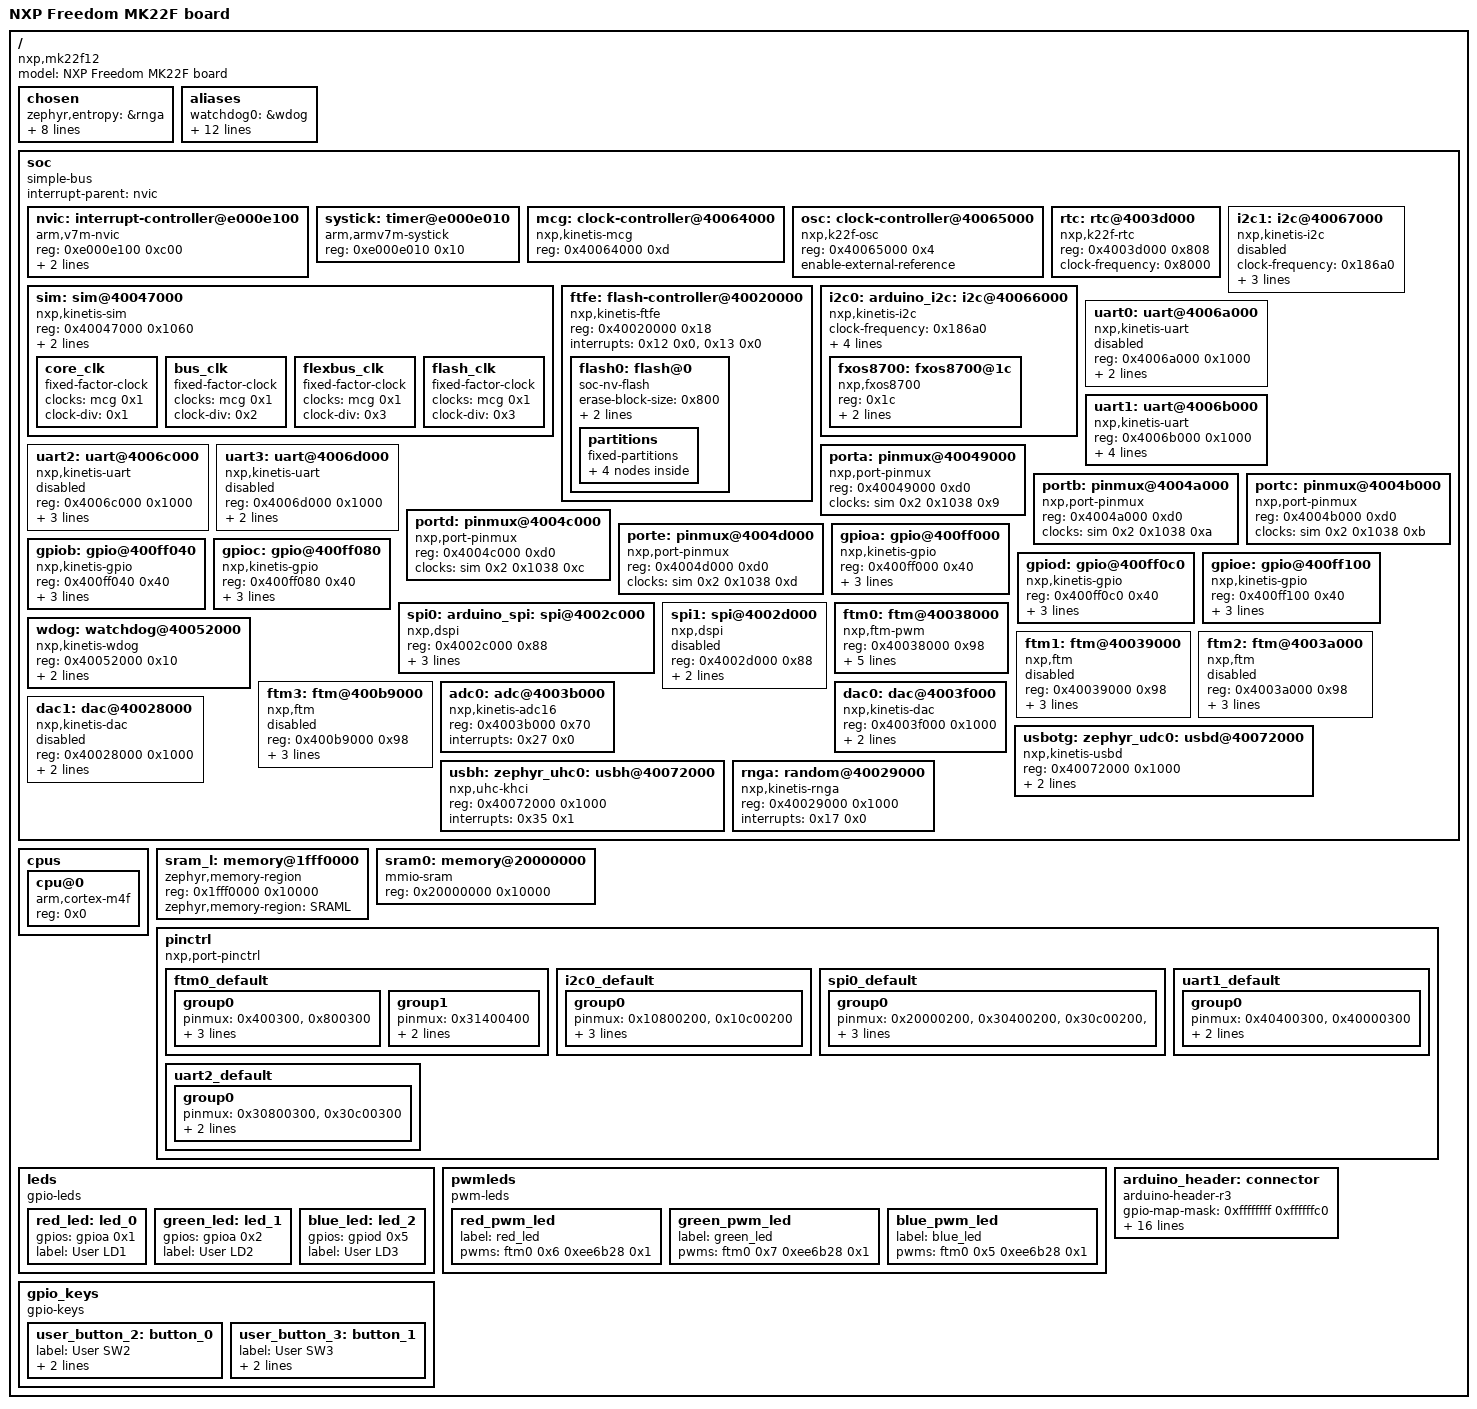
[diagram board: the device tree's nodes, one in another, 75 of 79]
/dts-v1/;

/* node '/' defined in zephyr/dts/common/skeleton.dtsi:9 */
/ {
	#address-cells = < 0x1 >;          /* in zephyr/dts/common/skeleton.dtsi:10 */
	#size-cells = < 0x1 >;             /* in zephyr/dts/common/skeleton.dtsi:11 */
	model = "NXP Freedom MK22F board"; /* in zephyr/boards/nxp/frdm_k22f/frdm_k22f.dts:17 */
	compatible = "nxp,mk22f12",
	             "nxp,k22f",
	             "nxp,k2x";            /* in zephyr/boards/nxp/frdm_k22f/frdm_k22f.dts:18 */

	/* node '/chosen' defined in zephyr/dts/common/skeleton.dtsi:13 */
	chosen {
		zephyr,entropy = &rnga;                   /* in zephyr/dts/arm/nxp/nxp_k2x.dtsi:19 */
		zephyr,flash-controller = &ftfe;          /* in zephyr/dts/arm/nxp/nxp_k2x.dtsi:20 */
		zephyr,sram = &sram0;                     /* in zephyr/boards/nxp/frdm_k22f/frdm_k22f.dts:36 */
		zephyr,flash = &flash0;                   /* in zephyr/boards/nxp/frdm_k22f/frdm_k22f.dts:37 */
		zephyr,code-partition = &slot0_partition; /* in zephyr/boards/nxp/frdm_k22f/frdm_k22f.dts:38 */
		zephyr,uart-mcumgr = &uart1;              /* in zephyr/boards/nxp/frdm_k22f/frdm_k22f.dts:39 */
		zephyr,console = &uart1;                  /* in zephyr/boards/nxp/frdm_k22f/frdm_k22f.dts:40 */
		zephyr,shell-uart = &uart1;               /* in zephyr/boards/nxp/frdm_k22f/frdm_k22f.dts:41 */
		zephyr,uart-pipe = &uart1;                /* in zephyr/boards/nxp/frdm_k22f/frdm_k22f.dts:42 */
	};

	/* node '/aliases' defined in zephyr/dts/common/skeleton.dtsi:15 */
	aliases {
		watchdog0 = &wdog;                /* in zephyr/dts/arm/nxp/nxp_k2x.dtsi:24 */
		led0 = &green_led;                /* in zephyr/boards/nxp/frdm_k22f/frdm_k22f.dts:21 */
		led1 = &blue_led;                 /* in zephyr/boards/nxp/frdm_k22f/frdm_k22f.dts:22 */
		led2 = &red_led;                  /* in zephyr/boards/nxp/frdm_k22f/frdm_k22f.dts:23 */
		sw0 = &user_button_3;             /* in zephyr/boards/nxp/frdm_k22f/frdm_k22f.dts:24 */
		sw1 = &user_button_2;             /* in zephyr/boards/nxp/frdm_k22f/frdm_k22f.dts:25 */
		pwm-led0 = &green_pwm_led;        /* in zephyr/boards/nxp/frdm_k22f/frdm_k22f.dts:26 */
		green-pwm-led = &green_pwm_led;   /* in zephyr/boards/nxp/frdm_k22f/frdm_k22f.dts:27 */
		blue-pwm-led = &blue_pwm_led;     /* in zephyr/boards/nxp/frdm_k22f/frdm_k22f.dts:28 */
		red-pwm-led = &red_pwm_led;       /* in zephyr/boards/nxp/frdm_k22f/frdm_k22f.dts:29 */
		magn0 = &fxos8700;                /* in zephyr/boards/nxp/frdm_k22f/frdm_k22f.dts:30 */
		accel0 = &fxos8700;               /* in zephyr/boards/nxp/frdm_k22f/frdm_k22f.dts:31 */
		mcuboot-button0 = &user_button_3; /* in zephyr/boards/nxp/frdm_k22f/frdm_k22f.dts:32 */
	};

	/* node '/soc' defined in zephyr/dts/arm/armv7-m.dtsi:6 */
	soc {
		#address-cells = < 0x1 >;     /* in zephyr/dts/arm/armv7-m.dtsi:7 */
		#size-cells = < 0x1 >;        /* in zephyr/dts/arm/armv7-m.dtsi:8 */
		compatible = "simple-bus";    /* in zephyr/dts/arm/armv7-m.dtsi:9 */
		interrupt-parent = < &nvic >; /* in zephyr/dts/arm/armv7-m.dtsi:10 */
		ranges;                       /* in zephyr/dts/arm/armv7-m.dtsi:11 */

		/* node '/soc/interrupt-controller@e000e100' defined in zephyr/dts/arm/armv7-m.dtsi:13 */
		nvic: interrupt-controller@e000e100 {
			#address-cells = < 0x1 >;            /* in zephyr/dts/arm/armv7-m.dtsi:14 */
			compatible = "arm,v7m-nvic";         /* in zephyr/dts/arm/armv7-m.dtsi:15 */
			reg = < 0xe000e100 0xc00 >;          /* in zephyr/dts/arm/armv7-m.dtsi:16 */
			interrupt-controller;                /* in zephyr/dts/arm/armv7-m.dtsi:17 */
			#interrupt-cells = < 0x2 >;          /* in zephyr/dts/arm/armv7-m.dtsi:18 */
			arm,num-irq-priority-bits = < 0x4 >; /* in zephyr/dts/arm/nxp/nxp_k2x.dtsi:398 */
			phandle = < 0x1 >;                   /* in zephyr/dts/arm/armv7-m.dtsi:10 */
		};

		/* node '/soc/timer@e000e010' defined in zephyr/dts/arm/armv7-m.dtsi:21 */
		systick: timer@e000e010 {
			compatible = "arm,armv7m-systick"; /* in zephyr/dts/arm/armv7-m.dtsi:22 */
			reg = < 0xe000e010 0x10 >;         /* in zephyr/dts/arm/armv7-m.dtsi:23 */
		};

		/* node '/soc/clock-controller@40064000' defined in zephyr/dts/arm/nxp/nxp_k2x.dtsi:65 */
		mcg: clock-controller@40064000 {
			compatible = "nxp,kinetis-mcg"; /* in zephyr/dts/arm/nxp/nxp_k2x.dtsi:66 */
			reg = < 0x40064000 0xd >;       /* in zephyr/dts/arm/nxp/nxp_k2x.dtsi:67 */
			#clock-cells = < 0x1 >;         /* in zephyr/dts/arm/nxp/nxp_k2x.dtsi:68 */
			phandle = < 0x2 >;              /* in zephyr/dts/arm/nxp/nxp_k2x.dtsi:91 */
		};

		/* node '/soc/clock-controller@40065000' defined in zephyr/dts/arm/nxp/nxp_k2x.dtsi:71 */
		osc: clock-controller@40065000 {
			compatible = "nxp,k22f-osc"; /* in zephyr/dts/arm/nxp/nxp_k2x.dtsi:72 */
			reg = < 0x40065000 0x4 >;    /* in zephyr/dts/arm/nxp/nxp_k2x.dtsi:73 */
			enable-external-reference;   /* in zephyr/dts/arm/nxp/nxp_k2x.dtsi:75 */
		};

		/* node '/soc/rtc@4003d000' defined in zephyr/dts/arm/nxp/nxp_k2x.dtsi:78 */
		rtc: rtc@4003d000 {
			compatible = "nxp,k22f-rtc";  /* in zephyr/dts/arm/nxp/nxp_k2x.dtsi:79 */
			reg = < 0x4003d000 0x808 >;   /* in zephyr/dts/arm/nxp/nxp_k2x.dtsi:80 */
			clock-frequency = < 0x8000 >; /* in zephyr/dts/arm/nxp/nxp_k2x.dtsi:81 */
		};

		/* node '/soc/sim@40047000' defined in zephyr/dts/arm/nxp/nxp_k2x.dtsi:84 */
		sim: sim@40047000 {
			compatible = "nxp,kinetis-sim"; /* in zephyr/dts/arm/nxp/nxp_k2x.dtsi:85 */
			reg = < 0x40047000 0x1060 >;    /* in zephyr/dts/arm/nxp/nxp_k2x.dtsi:86 */
			#clock-cells = < 0x3 >;         /* in zephyr/dts/arm/nxp/nxp_k2x.dtsi:87 */
			pllfll-select = < 0x1 >;        /* in zephyr/boards/nxp/frdm_k22f/frdm_k22f.dts:130 */
			er32k-select = < 0x2 >;         /* in zephyr/boards/nxp/frdm_k22f/frdm_k22f.dts:131 */
			phandle = < 0x3 >;              /* in zephyr/dts/arm/nxp/nxp_k2x.dtsi:143 */

			/* node '/soc/sim@40047000/core_clk' defined in zephyr/dts/arm/nxp/nxp_k2x.dtsi:89 */
			core_clk {
				compatible = "fixed-factor-clock"; /* in zephyr/dts/arm/nxp/nxp_k2x.dtsi:90 */
				clocks = < &mcg 0x1 >;             /* in zephyr/dts/arm/nxp/nxp_k2x.dtsi:91 */
				clock-div = < 0x1 >;               /* in zephyr/dts/arm/nxp/nxp_k2x.dtsi:92 */
				#clock-cells = < 0x0 >;            /* in zephyr/dts/arm/nxp/nxp_k2x.dtsi:93 */
			};

			/* node '/soc/sim@40047000/bus_clk' defined in zephyr/dts/arm/nxp/nxp_k2x.dtsi:96 */
			bus_clk {
				compatible = "fixed-factor-clock"; /* in zephyr/dts/arm/nxp/nxp_k2x.dtsi:97 */
				clocks = < &mcg 0x1 >;             /* in zephyr/dts/arm/nxp/nxp_k2x.dtsi:98 */
				clock-div = < 0x2 >;               /* in zephyr/dts/arm/nxp/nxp_k2x.dtsi:99 */
				#clock-cells = < 0x0 >;            /* in zephyr/dts/arm/nxp/nxp_k2x.dtsi:100 */
			};

			/* node '/soc/sim@40047000/flexbus_clk' defined in zephyr/dts/arm/nxp/nxp_k2x.dtsi:103 */
			flexbus_clk {
				compatible = "fixed-factor-clock"; /* in zephyr/dts/arm/nxp/nxp_k2x.dtsi:104 */
				clocks = < &mcg 0x1 >;             /* in zephyr/dts/arm/nxp/nxp_k2x.dtsi:105 */
				clock-div = < 0x3 >;               /* in zephyr/dts/arm/nxp/nxp_k2x.dtsi:106 */
				#clock-cells = < 0x0 >;            /* in zephyr/dts/arm/nxp/nxp_k2x.dtsi:107 */
			};

			/* node '/soc/sim@40047000/flash_clk' defined in zephyr/dts/arm/nxp/nxp_k2x.dtsi:110 */
			flash_clk {
				compatible = "fixed-factor-clock"; /* in zephyr/dts/arm/nxp/nxp_k2x.dtsi:111 */
				clocks = < &mcg 0x1 >;             /* in zephyr/dts/arm/nxp/nxp_k2x.dtsi:112 */
				clock-div = < 0x3 >;               /* in zephyr/dts/arm/nxp/nxp_k2x.dtsi:113 */
				#clock-cells = < 0x0 >;            /* in zephyr/dts/arm/nxp/nxp_k2x.dtsi:114 */
			};
		};

		/* node '/soc/flash-controller@40020000' defined in zephyr/dts/arm/nxp/nxp_k2x.dtsi:118 */
		ftfe: flash-controller@40020000 {
			compatible = "nxp,kinetis-ftfe";      /* in zephyr/dts/arm/nxp/nxp_k2x.dtsi:119 */
			reg = < 0x40020000 0x18 >;            /* in zephyr/dts/arm/nxp/nxp_k2x.dtsi:120 */
			interrupts = < 0x12 0x0 >,
			             < 0x13 0x0 >;            /* in zephyr/dts/arm/nxp/nxp_k2x.dtsi:121 */
			interrupt-names = "command-complete",
			                  "read-collision";   /* in zephyr/dts/arm/nxp/nxp_k2x.dtsi:122 */
			status = "okay";                      /* in zephyr/dts/arm/nxp/nxp_k2x.dtsi:123 */
			#address-cells = < 0x1 >;             /* in zephyr/dts/arm/nxp/nxp_k2x.dtsi:125 */
			#size-cells = < 0x1 >;                /* in zephyr/dts/arm/nxp/nxp_k2x.dtsi:126 */

			/* node '/soc/flash-controller@40020000/flash@0' defined in zephyr/dts/arm/nxp/nxp_k2x.dtsi:128 */
			flash0: flash@0 {
				compatible = "soc-nv-flash";  /* in zephyr/dts/arm/nxp/nxp_k2x.dtsi:129 */
				erase-block-size = < 0x800 >; /* in zephyr/dts/arm/nxp/nxp_k2x.dtsi:131 */
				write-block-size = < 0x8 >;   /* in zephyr/dts/arm/nxp/nxp_k2x.dtsi:132 */
				reg = < 0x0 0x80000 >;        /* in zephyr/dts/arm/nxp/nxp_k22fn512.dtsi:10 */

				/* node '/soc/flash-controller@40020000/flash@0/partitions' defined in zephyr/boards/nxp/frdm_k22f/frdm_k22f.dts:214 */
				partitions {
					compatible = "fixed-partitions"; /* in zephyr/boards/nxp/frdm_k22f/frdm_k22f.dts:215 */
					#address-cells = < 0x1 >;        /* in zephyr/boards/nxp/frdm_k22f/frdm_k22f.dts:216 */
					#size-cells = < 0x1 >;           /* in zephyr/boards/nxp/frdm_k22f/frdm_k22f.dts:217 */

					/* node '/soc/flash-controller@40020000/flash@0/partitions/partition@0' defined in zephyr/boards/nxp/frdm_k22f/frdm_k22f.dts:223 */
					boot_partition: partition@0 {
						label = "mcuboot";     /* in zephyr/boards/nxp/frdm_k22f/frdm_k22f.dts:224 */
						reg = < 0x0 0x10000 >; /* in zephyr/boards/nxp/frdm_k22f/frdm_k22f.dts:225 */
						read-only;             /* in zephyr/boards/nxp/frdm_k22f/frdm_k22f.dts:226 */
					};

					/* node '/soc/flash-controller@40020000/flash@0/partitions/partition@10000' defined in zephyr/boards/nxp/frdm_k22f/frdm_k22f.dts:229 */
					slot0_partition: partition@10000 {
						label = "image-0";         /* in zephyr/boards/nxp/frdm_k22f/frdm_k22f.dts:230 */
						reg = < 0x10000 0x2d800 >; /* in zephyr/boards/nxp/frdm_k22f/frdm_k22f.dts:231 */
					};

					/* node '/soc/flash-controller@40020000/flash@0/partitions/partition@3D800' defined in zephyr/boards/nxp/frdm_k22f/frdm_k22f.dts:234 */
					slot1_partition: partition@3D800 {
						label = "image-1";         /* in zephyr/boards/nxp/frdm_k22f/frdm_k22f.dts:235 */
						reg = < 0x3d800 0x2d800 >; /* in zephyr/boards/nxp/frdm_k22f/frdm_k22f.dts:236 */
					};

					/* node '/soc/flash-controller@40020000/flash@0/partitions/partition@6B000' defined in zephyr/boards/nxp/frdm_k22f/frdm_k22f.dts:239 */
					storage_partition: partition@6B000 {
						label = "storage";         /* in zephyr/boards/nxp/frdm_k22f/frdm_k22f.dts:240 */
						reg = < 0x6b000 0x15000 >; /* in zephyr/boards/nxp/frdm_k22f/frdm_k22f.dts:241 */
					};
				};
			};
		};

		/* node '/soc/i2c@40066000' defined in zephyr/dts/arm/nxp/nxp_k2x.dtsi:136 */
		i2c0: arduino_i2c: i2c@40066000 {
			compatible = "nxp,kinetis-i2c";   /* in zephyr/dts/arm/nxp/nxp_k2x.dtsi:137 */
			clock-frequency = < 0x186a0 >;    /* in zephyr/dts/arm/nxp/nxp_k2x.dtsi:138 */
			#address-cells = < 0x1 >;         /* in zephyr/dts/arm/nxp/nxp_k2x.dtsi:139 */
			#size-cells = < 0x0 >;            /* in zephyr/dts/arm/nxp/nxp_k2x.dtsi:140 */
			reg = < 0x40066000 0x1000 >;      /* in zephyr/dts/arm/nxp/nxp_k2x.dtsi:141 */
			interrupts = < 0x18 0x0 >;        /* in zephyr/dts/arm/nxp/nxp_k2x.dtsi:142 */
			clocks = < &sim 0x2 0x1034 0x6 >; /* in zephyr/dts/arm/nxp/nxp_k2x.dtsi:143 */
			status = "okay";                  /* in zephyr/boards/nxp/frdm_k22f/frdm_k22f.dts:144 */
			pinctrl-0 = < &i2c0_default >;    /* in zephyr/boards/nxp/frdm_k22f/frdm_k22f.dts:145 */
			pinctrl-names = "default";        /* in zephyr/boards/nxp/frdm_k22f/frdm_k22f.dts:146 */

			/* node '/soc/i2c@40066000/fxos8700@1c' defined in zephyr/boards/nxp/frdm_k22f/frdm_k22f.dts:148 */
			fxos8700: fxos8700@1c {
				compatible = "nxp,fxos8700";     /* in zephyr/boards/nxp/frdm_k22f/frdm_k22f.dts:149 */
				reg = < 0x1c >;                  /* in zephyr/boards/nxp/frdm_k22f/frdm_k22f.dts:150 */
				int1-gpios = < &gpiod 0x0 0x1 >; /* in zephyr/boards/nxp/frdm_k22f/frdm_k22f.dts:151 */
				int2-gpios = < &gpiod 0x1 0x1 >; /* in zephyr/boards/nxp/frdm_k22f/frdm_k22f.dts:152 */
			};
		};

		/* node '/soc/i2c@40067000' defined in zephyr/dts/arm/nxp/nxp_k2x.dtsi:147 */
		i2c1: i2c@40067000 {
			compatible = "nxp,kinetis-i2c";   /* in zephyr/dts/arm/nxp/nxp_k2x.dtsi:148 */
			clock-frequency = < 0x186a0 >;    /* in zephyr/dts/arm/nxp/nxp_k2x.dtsi:149 */
			#address-cells = < 0x1 >;         /* in zephyr/dts/arm/nxp/nxp_k2x.dtsi:150 */
			#size-cells = < 0x0 >;            /* in zephyr/dts/arm/nxp/nxp_k2x.dtsi:151 */
			reg = < 0x40067000 0x1000 >;      /* in zephyr/dts/arm/nxp/nxp_k2x.dtsi:152 */
			interrupts = < 0x19 0x0 >;        /* in zephyr/dts/arm/nxp/nxp_k2x.dtsi:153 */
			clocks = < &sim 0x2 0x1034 0x7 >; /* in zephyr/dts/arm/nxp/nxp_k2x.dtsi:154 */
			status = "disabled";              /* in zephyr/dts/arm/nxp/nxp_k2x.dtsi:155 */
		};

		/* node '/soc/uart@4006a000' defined in zephyr/dts/arm/nxp/nxp_k2x.dtsi:158 */
		uart0: uart@4006a000 {
			compatible = "nxp,kinetis-uart";  /* in zephyr/dts/arm/nxp/nxp_k2x.dtsi:159 */
			reg = < 0x4006a000 0x1000 >;      /* in zephyr/dts/arm/nxp/nxp_k2x.dtsi:160 */
			interrupts = < 0x1f 0x0 >,
			             < 0x20 0x0 >;        /* in zephyr/dts/arm/nxp/nxp_k2x.dtsi:161 */
			interrupt-names = "status",
			                  "error";        /* in zephyr/dts/arm/nxp/nxp_k2x.dtsi:162 */
			clocks = < &sim 0x0 0x1034 0xa >; /* in zephyr/dts/arm/nxp/nxp_k2x.dtsi:163 */
			status = "disabled";              /* in zephyr/dts/arm/nxp/nxp_k2x.dtsi:165 */
		};

		/* node '/soc/uart@4006b000' defined in zephyr/dts/arm/nxp/nxp_k2x.dtsi:168 */
		uart1: uart@4006b000 {
			compatible = "nxp,kinetis-uart";  /* in zephyr/dts/arm/nxp/nxp_k2x.dtsi:169 */
			reg = < 0x4006b000 0x1000 >;      /* in zephyr/dts/arm/nxp/nxp_k2x.dtsi:170 */
			interrupts = < 0x21 0x0 >,
			             < 0x22 0x0 >;        /* in zephyr/dts/arm/nxp/nxp_k2x.dtsi:171 */
			interrupt-names = "status",
			                  "error";        /* in zephyr/dts/arm/nxp/nxp_k2x.dtsi:172 */
			clocks = < &sim 0x0 0x1034 0xb >; /* in zephyr/dts/arm/nxp/nxp_k2x.dtsi:173 */
			status = "okay";                  /* in zephyr/boards/nxp/frdm_k22f/frdm_k22f.dts:172 */
			current-speed = < 0x1c200 >;      /* in zephyr/boards/nxp/frdm_k22f/frdm_k22f.dts:173 */
			pinctrl-0 = < &uart1_default >;   /* in zephyr/boards/nxp/frdm_k22f/frdm_k22f.dts:174 */
			pinctrl-names = "default";        /* in zephyr/boards/nxp/frdm_k22f/frdm_k22f.dts:175 */
		};

		/* node '/soc/uart@4006c000' defined in zephyr/dts/arm/nxp/nxp_k2x.dtsi:178 */
		uart2: uart@4006c000 {
			compatible = "nxp,kinetis-uart";  /* in zephyr/dts/arm/nxp/nxp_k2x.dtsi:179 */
			reg = < 0x4006c000 0x1000 >;      /* in zephyr/dts/arm/nxp/nxp_k2x.dtsi:180 */
			interrupts = < 0x23 0x0 >,
			             < 0x24 0x0 >;        /* in zephyr/dts/arm/nxp/nxp_k2x.dtsi:181 */
			interrupt-names = "status",
			                  "error";        /* in zephyr/dts/arm/nxp/nxp_k2x.dtsi:182 */
			clocks = < &sim 0x2 0x1034 0xc >; /* in zephyr/dts/arm/nxp/nxp_k2x.dtsi:183 */
			status = "disabled";              /* in zephyr/dts/arm/nxp/nxp_k2x.dtsi:185 */
			pinctrl-0 = < &uart2_default >;   /* in zephyr/boards/nxp/frdm_k22f/frdm_k22f.dts:179 */
			pinctrl-names = "default";        /* in zephyr/boards/nxp/frdm_k22f/frdm_k22f.dts:180 */
		};

		/* node '/soc/uart@4006d000' defined in zephyr/dts/arm/nxp/nxp_k2x.dtsi:188 */
		uart3: uart@4006d000 {
			compatible = "nxp,kinetis-uart";  /* in zephyr/dts/arm/nxp/nxp_k2x.dtsi:189 */
			reg = < 0x4006d000 0x1000 >;      /* in zephyr/dts/arm/nxp/nxp_k2x.dtsi:190 */
			interrupts = < 0x25 0x0 >,
			             < 0x26 0x0 >;        /* in zephyr/dts/arm/nxp/nxp_k2x.dtsi:191 */
			interrupt-names = "status",
			                  "error";        /* in zephyr/dts/arm/nxp/nxp_k2x.dtsi:192 */
			clocks = < &sim 0x2 0x1034 0xd >; /* in zephyr/dts/arm/nxp/nxp_k2x.dtsi:193 */
			status = "disabled";              /* in zephyr/dts/arm/nxp/nxp_k2x.dtsi:195 */
		};

		/* node '/soc/pinmux@40049000' defined in zephyr/dts/arm/nxp/nxp_k2x.dtsi:198 */
		porta: pinmux@40049000 {
			compatible = "nxp,port-pinmux";   /* in zephyr/dts/arm/nxp/nxp_k2x.dtsi:199 */
			reg = < 0x40049000 0xd0 >;        /* in zephyr/dts/arm/nxp/nxp_k2x.dtsi:200 */
			clocks = < &sim 0x2 0x1038 0x9 >; /* in zephyr/dts/arm/nxp/nxp_k2x.dtsi:201 */
			phandle = < 0x8 >;                /* in zephyr/dts/arm/nxp/nxp_k2x.dtsi:235 */
		};

		/* node '/soc/pinmux@4004a000' defined in zephyr/dts/arm/nxp/nxp_k2x.dtsi:204 */
		portb: pinmux@4004a000 {
			compatible = "nxp,port-pinmux";   /* in zephyr/dts/arm/nxp/nxp_k2x.dtsi:205 */
			reg = < 0x4004a000 0xd0 >;        /* in zephyr/dts/arm/nxp/nxp_k2x.dtsi:206 */
			clocks = < &sim 0x2 0x1038 0xa >; /* in zephyr/dts/arm/nxp/nxp_k2x.dtsi:207 */
			phandle = < 0x9 >;                /* in zephyr/dts/arm/nxp/nxp_k2x.dtsi:245 */
		};

		/* node '/soc/pinmux@4004b000' defined in zephyr/dts/arm/nxp/nxp_k2x.dtsi:210 */
		portc: pinmux@4004b000 {
			compatible = "nxp,port-pinmux";   /* in zephyr/dts/arm/nxp/nxp_k2x.dtsi:211 */
			reg = < 0x4004b000 0xd0 >;        /* in zephyr/dts/arm/nxp/nxp_k2x.dtsi:212 */
			clocks = < &sim 0x2 0x1038 0xb >; /* in zephyr/dts/arm/nxp/nxp_k2x.dtsi:213 */
			phandle = < 0xa >;                /* in zephyr/dts/arm/nxp/nxp_k2x.dtsi:255 */
		};

		/* node '/soc/pinmux@4004c000' defined in zephyr/dts/arm/nxp/nxp_k2x.dtsi:216 */
		portd: pinmux@4004c000 {
			compatible = "nxp,port-pinmux";   /* in zephyr/dts/arm/nxp/nxp_k2x.dtsi:217 */
			reg = < 0x4004c000 0xd0 >;        /* in zephyr/dts/arm/nxp/nxp_k2x.dtsi:218 */
			clocks = < &sim 0x2 0x1038 0xc >; /* in zephyr/dts/arm/nxp/nxp_k2x.dtsi:219 */
			phandle = < 0xb >;                /* in zephyr/dts/arm/nxp/nxp_k2x.dtsi:265 */
		};

		/* node '/soc/pinmux@4004d000' defined in zephyr/dts/arm/nxp/nxp_k2x.dtsi:222 */
		porte: pinmux@4004d000 {
			compatible = "nxp,port-pinmux";   /* in zephyr/dts/arm/nxp/nxp_k2x.dtsi:223 */
			reg = < 0x4004d000 0xd0 >;        /* in zephyr/dts/arm/nxp/nxp_k2x.dtsi:224 */
			clocks = < &sim 0x2 0x1038 0xd >; /* in zephyr/dts/arm/nxp/nxp_k2x.dtsi:225 */
			phandle = < 0xc >;                /* in zephyr/dts/arm/nxp/nxp_k2x.dtsi:275 */
		};

		/* node '/soc/gpio@400ff000' defined in zephyr/dts/arm/nxp/nxp_k2x.dtsi:228 */
		gpioa: gpio@400ff000 {
			compatible = "nxp,kinetis-gpio"; /* in zephyr/dts/arm/nxp/nxp_k2x.dtsi:229 */
			reg = < 0x400ff000 0x40 >;       /* in zephyr/dts/arm/nxp/nxp_k2x.dtsi:231 */
			interrupts = < 0x3b 0x2 >;       /* in zephyr/dts/arm/nxp/nxp_k2x.dtsi:232 */
			gpio-controller;                 /* in zephyr/dts/arm/nxp/nxp_k2x.dtsi:233 */
			#gpio-cells = < 0x2 >;           /* in zephyr/dts/arm/nxp/nxp_k2x.dtsi:234 */
			nxp,kinetis-port = < &porta >;   /* in zephyr/dts/arm/nxp/nxp_k2x.dtsi:235 */
			status = "okay";                 /* in zephyr/boards/nxp/frdm_k22f/frdm_k22f.dts:194 */
			phandle = < 0xf >;               /* in zephyr/boards/nxp/frdm_k22f/frdm_k22f.dts:49 */
		};

		/* node '/soc/gpio@400ff040' defined in zephyr/dts/arm/nxp/nxp_k2x.dtsi:238 */
		gpiob: gpio@400ff040 {
			compatible = "nxp,kinetis-gpio"; /* in zephyr/dts/arm/nxp/nxp_k2x.dtsi:239 */
			reg = < 0x400ff040 0x40 >;       /* in zephyr/dts/arm/nxp/nxp_k2x.dtsi:241 */
			interrupts = < 0x3c 0x2 >;       /* in zephyr/dts/arm/nxp/nxp_k2x.dtsi:242 */
			gpio-controller;                 /* in zephyr/dts/arm/nxp/nxp_k2x.dtsi:243 */
			#gpio-cells = < 0x2 >;           /* in zephyr/dts/arm/nxp/nxp_k2x.dtsi:244 */
			nxp,kinetis-port = < &portb >;   /* in zephyr/dts/arm/nxp/nxp_k2x.dtsi:245 */
			status = "okay";                 /* in zephyr/boards/nxp/frdm_k22f/frdm_k22f.dts:198 */
			phandle = < 0x12 >;              /* in zephyr/boards/nxp/frdm_k22f/frdm_k22f.dts:94 */
		};

		/* node '/soc/gpio@400ff080' defined in zephyr/dts/arm/nxp/nxp_k2x.dtsi:248 */
		gpioc: gpio@400ff080 {
			compatible = "nxp,kinetis-gpio"; /* in zephyr/dts/arm/nxp/nxp_k2x.dtsi:249 */
			reg = < 0x400ff080 0x40 >;       /* in zephyr/dts/arm/nxp/nxp_k2x.dtsi:251 */
			interrupts = < 0x3d 0x2 >;       /* in zephyr/dts/arm/nxp/nxp_k2x.dtsi:252 */
			gpio-controller;                 /* in zephyr/dts/arm/nxp/nxp_k2x.dtsi:253 */
			#gpio-cells = < 0x2 >;           /* in zephyr/dts/arm/nxp/nxp_k2x.dtsi:254 */
			nxp,kinetis-port = < &portc >;   /* in zephyr/dts/arm/nxp/nxp_k2x.dtsi:255 */
			status = "okay";                 /* in zephyr/boards/nxp/frdm_k22f/frdm_k22f.dts:202 */
			phandle = < 0x11 >;              /* in zephyr/boards/nxp/frdm_k22f/frdm_k22f.dts:88 */
		};

		/* node '/soc/gpio@400ff0c0' defined in zephyr/dts/arm/nxp/nxp_k2x.dtsi:258 */
		gpiod: gpio@400ff0c0 {
			compatible = "nxp,kinetis-gpio"; /* in zephyr/dts/arm/nxp/nxp_k2x.dtsi:259 */
			reg = < 0x400ff0c0 0x40 >;       /* in zephyr/dts/arm/nxp/nxp_k2x.dtsi:261 */
			interrupts = < 0x3e 0x2 >;       /* in zephyr/dts/arm/nxp/nxp_k2x.dtsi:262 */
			gpio-controller;                 /* in zephyr/dts/arm/nxp/nxp_k2x.dtsi:263 */
			#gpio-cells = < 0x2 >;           /* in zephyr/dts/arm/nxp/nxp_k2x.dtsi:264 */
			nxp,kinetis-port = < &portd >;   /* in zephyr/dts/arm/nxp/nxp_k2x.dtsi:265 */
			status = "okay";                 /* in zephyr/boards/nxp/frdm_k22f/frdm_k22f.dts:206 */
			phandle = < 0x5 >;               /* in zephyr/boards/nxp/frdm_k22f/frdm_k22f.dts:151 */
		};

		/* node '/soc/gpio@400ff100' defined in zephyr/dts/arm/nxp/nxp_k2x.dtsi:268 */
		gpioe: gpio@400ff100 {
			compatible = "nxp,kinetis-gpio"; /* in zephyr/dts/arm/nxp/nxp_k2x.dtsi:269 */
			reg = < 0x400ff100 0x40 >;       /* in zephyr/dts/arm/nxp/nxp_k2x.dtsi:271 */
			interrupts = < 0x3f 0x2 >;       /* in zephyr/dts/arm/nxp/nxp_k2x.dtsi:272 */
			gpio-controller;                 /* in zephyr/dts/arm/nxp/nxp_k2x.dtsi:273 */
			#gpio-cells = < 0x2 >;           /* in zephyr/dts/arm/nxp/nxp_k2x.dtsi:274 */
			nxp,kinetis-port = < &porte >;   /* in zephyr/dts/arm/nxp/nxp_k2x.dtsi:275 */
			status = "okay";                 /* in zephyr/boards/nxp/frdm_k22f/frdm_k22f.dts:210 */
			phandle = < 0x13 >;              /* in zephyr/boards/nxp/frdm_k22f/frdm_k22f.dts:104 */
		};

		/* node '/soc/spi@4002c000' defined in zephyr/dts/arm/nxp/nxp_k2x.dtsi:278 */
		spi0: arduino_spi: spi@4002c000 {
			compatible = "nxp,dspi";          /* in zephyr/dts/arm/nxp/nxp_k2x.dtsi:279 */
			reg = < 0x4002c000 0x88 >;        /* in zephyr/dts/arm/nxp/nxp_k2x.dtsi:280 */
			interrupts = < 0x1a 0x3 >;        /* in zephyr/dts/arm/nxp/nxp_k2x.dtsi:281 */
			clocks = < &sim 0x2 0x103c 0xc >; /* in zephyr/dts/arm/nxp/nxp_k2x.dtsi:282 */
			#address-cells = < 0x1 >;         /* in zephyr/dts/arm/nxp/nxp_k2x.dtsi:283 */
			#size-cells = < 0x0 >;            /* in zephyr/dts/arm/nxp/nxp_k2x.dtsi:284 */
			status = "okay";                  /* in zephyr/boards/nxp/frdm_k22f/frdm_k22f.dts:157 */
			pinctrl-0 = < &spi0_default >;    /* in zephyr/boards/nxp/frdm_k22f/frdm_k22f.dts:158 */
			pinctrl-names = "default";        /* in zephyr/boards/nxp/frdm_k22f/frdm_k22f.dts:159 */
		};

		/* node '/soc/spi@4002d000' defined in zephyr/dts/arm/nxp/nxp_k2x.dtsi:288 */
		spi1: spi@4002d000 {
			compatible = "nxp,dspi";          /* in zephyr/dts/arm/nxp/nxp_k2x.dtsi:289 */
			reg = < 0x4002d000 0x88 >;        /* in zephyr/dts/arm/nxp/nxp_k2x.dtsi:290 */
			interrupts = < 0x1b 0x3 >;        /* in zephyr/dts/arm/nxp/nxp_k2x.dtsi:291 */
			clocks = < &sim 0x2 0x103c 0xd >; /* in zephyr/dts/arm/nxp/nxp_k2x.dtsi:292 */
			#address-cells = < 0x1 >;         /* in zephyr/dts/arm/nxp/nxp_k2x.dtsi:293 */
			#size-cells = < 0x0 >;            /* in zephyr/dts/arm/nxp/nxp_k2x.dtsi:294 */
			status = "disabled";              /* in zephyr/dts/arm/nxp/nxp_k2x.dtsi:295 */
		};

		/* node '/soc/watchdog@40052000' defined in zephyr/dts/arm/nxp/nxp_k2x.dtsi:298 */
		wdog: watchdog@40052000 {
			compatible = "nxp,kinetis-wdog"; /* in zephyr/dts/arm/nxp/nxp_k2x.dtsi:299 */
			reg = < 0x40052000 0x10 >;       /* in zephyr/dts/arm/nxp/nxp_k2x.dtsi:300 */
			interrupts = < 0x16 0x0 >;       /* in zephyr/dts/arm/nxp/nxp_k2x.dtsi:301 */
			clocks = < &sim 0x13 0x0 0x0 >;  /* in zephyr/dts/arm/nxp/nxp_k2x.dtsi:302 */
		};

		/* node '/soc/ftm@40038000' defined in zephyr/dts/arm/nxp/nxp_k2x.dtsi:305 */
		ftm0: ftm@40038000 {
			reg = < 0x40038000 0x98 >;         /* in zephyr/dts/arm/nxp/nxp_k2x.dtsi:307 */
			interrupts = < 0x2a 0x0 >;         /* in zephyr/dts/arm/nxp/nxp_k2x.dtsi:308 */
			clocks = < &mcg 0x0 >,
			         < &sim 0x2 0x103c 0x18 >; /* in zephyr/dts/arm/nxp/nxp_k2x.dtsi:309 */
			prescaler = < 0x10 >;              /* in zephyr/dts/arm/nxp/nxp_k2x.dtsi:311 */
			status = "okay";                   /* in zephyr/boards/nxp/frdm_k22f/frdm_k22f.dts:163 */
			compatible = "nxp,ftm-pwm";        /* in zephyr/boards/nxp/frdm_k22f/frdm_k22f.dts:164 */
			#pwm-cells = < 0x3 >;              /* in zephyr/boards/nxp/frdm_k22f/frdm_k22f.dts:165 */
			pinctrl-0 = < &ftm0_default >;     /* in zephyr/boards/nxp/frdm_k22f/frdm_k22f.dts:166 */
			pinctrl-names = "default";         /* in zephyr/boards/nxp/frdm_k22f/frdm_k22f.dts:167 */
			clock-source = "fixed";            /* in zephyr/boards/nxp/frdm_k22f/frdm_k22f.dts:168 */
			phandle = < 0x10 >;                /* in zephyr/boards/nxp/frdm_k22f/frdm_k22f.dts:69 */
		};

		/* node '/soc/ftm@40039000' defined in zephyr/dts/arm/nxp/nxp_k2x.dtsi:315 */
		ftm1: ftm@40039000 {
			compatible = "nxp,ftm";            /* in zephyr/dts/arm/nxp/nxp_k2x.dtsi:316 */
			reg = < 0x40039000 0x98 >;         /* in zephyr/dts/arm/nxp/nxp_k2x.dtsi:317 */
			interrupts = < 0x2b 0x0 >;         /* in zephyr/dts/arm/nxp/nxp_k2x.dtsi:318 */
			clocks = < &mcg 0x0 >,
			         < &sim 0x2 0x103c 0x19 >; /* in zephyr/dts/arm/nxp/nxp_k2x.dtsi:319 */
			prescaler = < 0x10 >;              /* in zephyr/dts/arm/nxp/nxp_k2x.dtsi:321 */
			status = "disabled";               /* in zephyr/dts/arm/nxp/nxp_k2x.dtsi:322 */
		};

		/* node '/soc/ftm@4003a000' defined in zephyr/dts/arm/nxp/nxp_k2x.dtsi:325 */
		ftm2: ftm@4003a000 {
			compatible = "nxp,ftm";            /* in zephyr/dts/arm/nxp/nxp_k2x.dtsi:326 */
			reg = < 0x4003a000 0x98 >;         /* in zephyr/dts/arm/nxp/nxp_k2x.dtsi:327 */
			interrupts = < 0x2c 0x0 >;         /* in zephyr/dts/arm/nxp/nxp_k2x.dtsi:328 */
			clocks = < &mcg 0x0 >,
			         < &sim 0x2 0x103c 0x1a >; /* in zephyr/dts/arm/nxp/nxp_k2x.dtsi:329 */
			prescaler = < 0x10 >;              /* in zephyr/dts/arm/nxp/nxp_k2x.dtsi:331 */
			status = "disabled";               /* in zephyr/dts/arm/nxp/nxp_k2x.dtsi:332 */
		};

		/* node '/soc/ftm@400b9000' defined in zephyr/dts/arm/nxp/nxp_k2x.dtsi:335 */
		ftm3: ftm@400b9000 {
			compatible = "nxp,ftm";           /* in zephyr/dts/arm/nxp/nxp_k2x.dtsi:336 */
			reg = < 0x400b9000 0x98 >;        /* in zephyr/dts/arm/nxp/nxp_k2x.dtsi:337 */
			interrupts = < 0x47 0x0 >;        /* in zephyr/dts/arm/nxp/nxp_k2x.dtsi:338 */
			clocks = < &mcg 0x0 >,
			         < &sim 0x2 0x103c 0x6 >; /* in zephyr/dts/arm/nxp/nxp_k2x.dtsi:339 */
			prescaler = < 0x10 >;             /* in zephyr/dts/arm/nxp/nxp_k2x.dtsi:341 */
			status = "disabled";              /* in zephyr/dts/arm/nxp/nxp_k2x.dtsi:342 */
		};

		/* node '/soc/adc@4003b000' defined in zephyr/dts/arm/nxp/nxp_k2x.dtsi:345 */
		adc0: adc@4003b000 {
			compatible = "nxp,kinetis-adc16"; /* in zephyr/dts/arm/nxp/nxp_k2x.dtsi:346 */
			reg = < 0x4003b000 0x70 >;        /* in zephyr/dts/arm/nxp/nxp_k2x.dtsi:347 */
			interrupts = < 0x27 0x0 >;        /* in zephyr/dts/arm/nxp/nxp_k2x.dtsi:348 */
			#io-channel-cells = < 0x1 >;      /* in zephyr/dts/arm/nxp/nxp_k2x.dtsi:350 */
			status = "okay";                  /* in zephyr/boards/nxp/frdm_k22f/frdm_k22f.dts:135 */
		};

		/* node '/soc/dac@4003f000' defined in zephyr/dts/arm/nxp/nxp_k2x.dtsi:353 */
		dac0: dac@4003f000 {
			compatible = "nxp,kinetis-dac"; /* in zephyr/dts/arm/nxp/nxp_k2x.dtsi:354 */
			reg = < 0x4003f000 0x1000 >;    /* in zephyr/dts/arm/nxp/nxp_k2x.dtsi:355 */
			interrupts = < 0x38 0x0 >;      /* in zephyr/dts/arm/nxp/nxp_k2x.dtsi:356 */
			#io-channel-cells = < 0x1 >;    /* in zephyr/dts/arm/nxp/nxp_k2x.dtsi:359 */
			status = "okay";                /* in zephyr/boards/nxp/frdm_k22f/frdm_k22f.dts:139 */
			voltage-reference = < 0x2 >;    /* in zephyr/boards/nxp/frdm_k22f/frdm_k22f.dts:140 */
		};

		/* node '/soc/dac@40028000' defined in zephyr/dts/arm/nxp/nxp_k2x.dtsi:362 */
		dac1: dac@40028000 {
			compatible = "nxp,kinetis-dac"; /* in zephyr/dts/arm/nxp/nxp_k2x.dtsi:363 */
			reg = < 0x40028000 0x1000 >;    /* in zephyr/dts/arm/nxp/nxp_k2x.dtsi:364 */
			interrupts = < 0x48 0x0 >;      /* in zephyr/dts/arm/nxp/nxp_k2x.dtsi:365 */
			voltage-reference = < 0x1 >;    /* in zephyr/dts/arm/nxp/nxp_k2x.dtsi:366 */
			status = "disabled";            /* in zephyr/dts/arm/nxp/nxp_k2x.dtsi:367 */
			#io-channel-cells = < 0x1 >;    /* in zephyr/dts/arm/nxp/nxp_k2x.dtsi:368 */
		};

		/* node '/soc/usbd@40072000' defined in zephyr/dts/arm/nxp/nxp_k2x.dtsi:371 */
		usbotg: zephyr_udc0: usbd@40072000 {
			reg = < 0x40072000 0x1000 >;     /* in zephyr/dts/arm/nxp/nxp_k2x.dtsi:373 */
			interrupts = < 0x35 0x1 >;       /* in zephyr/dts/arm/nxp/nxp_k2x.dtsi:374 */
			interrupt-names = "usb_otg";     /* in zephyr/dts/arm/nxp/nxp_k2x.dtsi:375 */
			compatible = "nxp,kinetis-usbd"; /* in zephyr/boards/nxp/frdm_k22f/frdm_k22f.dts:184 */
			status = "okay";                 /* in zephyr/boards/nxp/frdm_k22f/frdm_k22f.dts:185 */
			num-bidir-endpoints = < 0x8 >;   /* in zephyr/boards/nxp/frdm_k22f/frdm_k22f.dts:186 */
		};

		/* node '/soc/usbh@40072000' defined in zephyr/dts/arm/nxp/nxp_k2x.dtsi:380 */
		usbh: zephyr_uhc0: usbh@40072000 {
			compatible = "nxp,uhc-khci"; /* in zephyr/dts/arm/nxp/nxp_k2x.dtsi:381 */
			reg = < 0x40072000 0x1000 >; /* in zephyr/dts/arm/nxp/nxp_k2x.dtsi:382 */
			interrupts = < 0x35 0x1 >;   /* in zephyr/dts/arm/nxp/nxp_k2x.dtsi:383 */
			interrupt-names = "usb_otg"; /* in zephyr/dts/arm/nxp/nxp_k2x.dtsi:384 */
			status = "okay";             /* in zephyr/boards/nxp/frdm_k22f/frdm_k22f.dts:190 */
		};

		/* node '/soc/random@40029000' defined in zephyr/dts/arm/nxp/nxp_k2x.dtsi:388 */
		rnga: random@40029000 {
			compatible = "nxp,kinetis-rnga"; /* in zephyr/dts/arm/nxp/nxp_k2x.dtsi:389 */
			reg = < 0x40029000 0x1000 >;     /* in zephyr/dts/arm/nxp/nxp_k2x.dtsi:390 */
			status = "okay";                 /* in zephyr/dts/arm/nxp/nxp_k2x.dtsi:391 */
			interrupts = < 0x17 0x0 >;       /* in zephyr/dts/arm/nxp/nxp_k2x.dtsi:392 */
		};
	};

	/* node '/cpus' defined in zephyr/dts/arm/nxp/nxp_k2x.dtsi:27 */
	cpus {
		#address-cells = < 0x1 >; /* in zephyr/dts/arm/nxp/nxp_k2x.dtsi:28 */
		#size-cells = < 0x0 >;    /* in zephyr/dts/arm/nxp/nxp_k2x.dtsi:29 */

		/* node '/cpus/cpu@0' defined in zephyr/dts/arm/nxp/nxp_k2x.dtsi:31 */
		cpu@0 {
			device_type = "cpu";           /* in zephyr/dts/arm/nxp/nxp_k2x.dtsi:32 */
			compatible = "arm,cortex-m4f"; /* in zephyr/dts/arm/nxp/nxp_k2x.dtsi:33 */
			reg = < 0x0 >;                 /* in zephyr/dts/arm/nxp/nxp_k2x.dtsi:34 */
		};
	};

	/* node '/memory@1fff0000' defined in zephyr/dts/arm/nxp/nxp_k2x.dtsi:47 */
	sram_l: memory@1fff0000 {
		compatible = "zephyr,memory-region",
		             "mmio-sram";            /* in zephyr/dts/arm/nxp/nxp_k2x.dtsi:48 */
		reg = < 0x1fff0000 0x10000 >;        /* in zephyr/dts/arm/nxp/nxp_k2x.dtsi:49 */
		zephyr,memory-region = "SRAML";      /* in zephyr/dts/arm/nxp/nxp_k2x.dtsi:50 */
	};

	/* node '/memory@20000000' defined in zephyr/dts/arm/nxp/nxp_k2x.dtsi:53 */
	sram0: memory@20000000 {
		compatible = "mmio-sram";     /* in zephyr/dts/arm/nxp/nxp_k2x.dtsi:54 */
		reg = < 0x20000000 0x10000 >; /* in zephyr/dts/arm/nxp/nxp_k2x.dtsi:55 */
	};

	/* node '/pinctrl' defined in zephyr/dts/arm/nxp/nxp_k2x.dtsi:59 */
	pinctrl: pinctrl {
		compatible = "nxp,port-pinctrl"; /* in zephyr/dts/arm/nxp/nxp_k2x.dtsi:60 */
		status = "okay";                 /* in zephyr/dts/arm/nxp/nxp_k2x.dtsi:61 */

		/* node '/pinctrl/ftm0_default' defined in zephyr/boards/nxp/frdm_k22f/frdm_k22f-pinctrl.dtsi:12 */
		ftm0_default: ftm0_default {
			phandle = < 0xe >; /* in zephyr/boards/nxp/frdm_k22f/frdm_k22f.dts:166 */

			/* node '/pinctrl/ftm0_default/group0' defined in zephyr/boards/nxp/frdm_k22f/frdm_k22f-pinctrl.dtsi:13 */
			group0 {
				pinmux = < 0x400300 >,
				         < 0x800300 >;  /* in zephyr/boards/nxp/frdm_k22f/frdm_k22f-pinctrl.dtsi:14 */
				drive-strength = "low"; /* in zephyr/boards/nxp/frdm_k22f/frdm_k22f-pinctrl.dtsi:16 */
				bias-pull-up;           /* in zephyr/boards/nxp/frdm_k22f/frdm_k22f-pinctrl.dtsi:17 */
				slew-rate = "fast";     /* in zephyr/boards/nxp/frdm_k22f/frdm_k22f-pinctrl.dtsi:18 */
			};

			/* node '/pinctrl/ftm0_default/group1' defined in zephyr/boards/nxp/frdm_k22f/frdm_k22f-pinctrl.dtsi:21 */
			group1 {
				pinmux = < 0x31400400 >; /* in zephyr/boards/nxp/frdm_k22f/frdm_k22f-pinctrl.dtsi:22 */
				drive-strength = "low";  /* in zephyr/boards/nxp/frdm_k22f/frdm_k22f-pinctrl.dtsi:23 */
				slew-rate = "fast";      /* in zephyr/boards/nxp/frdm_k22f/frdm_k22f-pinctrl.dtsi:24 */
			};
		};

		/* node '/pinctrl/i2c0_default' defined in zephyr/boards/nxp/frdm_k22f/frdm_k22f-pinctrl.dtsi:28 */
		i2c0_default: i2c0_default {
			phandle = < 0x4 >; /* in zephyr/boards/nxp/frdm_k22f/frdm_k22f.dts:145 */

			/* node '/pinctrl/i2c0_default/group0' defined in zephyr/boards/nxp/frdm_k22f/frdm_k22f-pinctrl.dtsi:29 */
			group0 {
				pinmux = < 0x10800200 >,
				         < 0x10c00200 >; /* in zephyr/boards/nxp/frdm_k22f/frdm_k22f-pinctrl.dtsi:30 */
				drive-strength = "low";  /* in zephyr/boards/nxp/frdm_k22f/frdm_k22f-pinctrl.dtsi:32 */
				drive-open-drain;        /* in zephyr/boards/nxp/frdm_k22f/frdm_k22f-pinctrl.dtsi:33 */
				slew-rate = "fast";      /* in zephyr/boards/nxp/frdm_k22f/frdm_k22f-pinctrl.dtsi:34 */
			};
		};

		/* node '/pinctrl/spi0_default' defined in zephyr/boards/nxp/frdm_k22f/frdm_k22f-pinctrl.dtsi:38 */
		spi0_default: spi0_default {
			phandle = < 0xd >; /* in zephyr/boards/nxp/frdm_k22f/frdm_k22f.dts:158 */

			/* node '/pinctrl/spi0_default/group0' defined in zephyr/boards/nxp/frdm_k22f/frdm_k22f-pinctrl.dtsi:39 */
			group0 {
				pinmux = < 0x20000200 >,
				         < 0x30400200 >,
				         < 0x30c00200 >,
				         < 0x30800200 >; /* in zephyr/boards/nxp/frdm_k22f/frdm_k22f-pinctrl.dtsi:40 */
				drive-strength = "low";  /* in zephyr/boards/nxp/frdm_k22f/frdm_k22f-pinctrl.dtsi:44 */
				slew-rate = "fast";      /* in zephyr/boards/nxp/frdm_k22f/frdm_k22f-pinctrl.dtsi:45 */
			};
		};

		/* node '/pinctrl/uart1_default' defined in zephyr/boards/nxp/frdm_k22f/frdm_k22f-pinctrl.dtsi:49 */
		uart1_default: uart1_default {
			phandle = < 0x6 >; /* in zephyr/boards/nxp/frdm_k22f/frdm_k22f.dts:174 */

			/* node '/pinctrl/uart1_default/group0' defined in zephyr/boards/nxp/frdm_k22f/frdm_k22f-pinctrl.dtsi:50 */
			group0 {
				pinmux = < 0x40400300 >,
				         < 0x40000300 >; /* in zephyr/boards/nxp/frdm_k22f/frdm_k22f-pinctrl.dtsi:51 */
				drive-strength = "low";  /* in zephyr/boards/nxp/frdm_k22f/frdm_k22f-pinctrl.dtsi:53 */
				slew-rate = "fast";      /* in zephyr/boards/nxp/frdm_k22f/frdm_k22f-pinctrl.dtsi:54 */
			};
		};

		/* node '/pinctrl/uart2_default' defined in zephyr/boards/nxp/frdm_k22f/frdm_k22f-pinctrl.dtsi:58 */
		uart2_default: uart2_default {
			phandle = < 0x7 >; /* in zephyr/boards/nxp/frdm_k22f/frdm_k22f.dts:179 */

			/* node '/pinctrl/uart2_default/group0' defined in zephyr/boards/nxp/frdm_k22f/frdm_k22f-pinctrl.dtsi:59 */
			group0 {
				pinmux = < 0x30800300 >,
				         < 0x30c00300 >; /* in zephyr/boards/nxp/frdm_k22f/frdm_k22f-pinctrl.dtsi:60 */
				drive-strength = "low";  /* in zephyr/boards/nxp/frdm_k22f/frdm_k22f-pinctrl.dtsi:62 */
				slew-rate = "fast";      /* in zephyr/boards/nxp/frdm_k22f/frdm_k22f-pinctrl.dtsi:63 */
			};
		};
	};

	/* node '/leds' defined in zephyr/boards/nxp/frdm_k22f/frdm_k22f.dts:45 */
	leds {
		compatible = "gpio-leds"; /* in zephyr/boards/nxp/frdm_k22f/frdm_k22f.dts:46 */

		/* node '/leds/led_0' defined in zephyr/boards/nxp/frdm_k22f/frdm_k22f.dts:48 */
		red_led: led_0 {
			gpios = < &gpioa 0x1 0x0 >; /* in zephyr/boards/nxp/frdm_k22f/frdm_k22f.dts:49 */
			label = "User LD1";         /* in zephyr/boards/nxp/frdm_k22f/frdm_k22f.dts:50 */
		};

		/* node '/leds/led_1' defined in zephyr/boards/nxp/frdm_k22f/frdm_k22f.dts:53 */
		green_led: led_1 {
			gpios = < &gpioa 0x2 0x0 >; /* in zephyr/boards/nxp/frdm_k22f/frdm_k22f.dts:54 */
			label = "User LD2";         /* in zephyr/boards/nxp/frdm_k22f/frdm_k22f.dts:55 */
		};

		/* node '/leds/led_2' defined in zephyr/boards/nxp/frdm_k22f/frdm_k22f.dts:58 */
		blue_led: led_2 {
			gpios = < &gpiod 0x5 0x0 >; /* in zephyr/boards/nxp/frdm_k22f/frdm_k22f.dts:59 */
			label = "User LD3";         /* in zephyr/boards/nxp/frdm_k22f/frdm_k22f.dts:60 */
		};
	};

	/* node '/pwmleds' defined in zephyr/boards/nxp/frdm_k22f/frdm_k22f.dts:64 */
	pwmleds {
		compatible = "pwm-leds"; /* in zephyr/boards/nxp/frdm_k22f/frdm_k22f.dts:65 */

		/* node '/pwmleds/red_pwm_led' defined in zephyr/boards/nxp/frdm_k22f/frdm_k22f.dts:67 */
		red_pwm_led: red_pwm_led {
			label = "red_led";                 /* in zephyr/boards/nxp/frdm_k22f/frdm_k22f.dts:68 */
			pwms = < &ftm0 0x6 0xee6b28 0x1 >; /* in zephyr/boards/nxp/frdm_k22f/frdm_k22f.dts:69 */
		};

		/* node '/pwmleds/green_pwm_led' defined in zephyr/boards/nxp/frdm_k22f/frdm_k22f.dts:72 */
		green_pwm_led: green_pwm_led {
			label = "green_led";               /* in zephyr/boards/nxp/frdm_k22f/frdm_k22f.dts:73 */
			pwms = < &ftm0 0x7 0xee6b28 0x1 >; /* in zephyr/boards/nxp/frdm_k22f/frdm_k22f.dts:74 */
		};

		/* node '/pwmleds/blue_pwm_led' defined in zephyr/boards/nxp/frdm_k22f/frdm_k22f.dts:77 */
		blue_pwm_led: blue_pwm_led {
			label = "blue_led";                /* in zephyr/boards/nxp/frdm_k22f/frdm_k22f.dts:78 */
			pwms = < &ftm0 0x5 0xee6b28 0x1 >; /* in zephyr/boards/nxp/frdm_k22f/frdm_k22f.dts:79 */
		};
	};

	/* node '/gpio_keys' defined in zephyr/boards/nxp/frdm_k22f/frdm_k22f.dts:83 */
	gpio_keys {
		compatible = "gpio-keys"; /* in zephyr/boards/nxp/frdm_k22f/frdm_k22f.dts:84 */

		/* node '/gpio_keys/button_0' defined in zephyr/boards/nxp/frdm_k22f/frdm_k22f.dts:86 */
		user_button_2: button_0 {
			label = "User SW2";         /* in zephyr/boards/nxp/frdm_k22f/frdm_k22f.dts:87 */
			gpios = < &gpioc 0x1 0x1 >; /* in zephyr/boards/nxp/frdm_k22f/frdm_k22f.dts:88 */
			zephyr,code = < 0xb >;      /* in zephyr/boards/nxp/frdm_k22f/frdm_k22f.dts:89 */
		};

		/* node '/gpio_keys/button_1' defined in zephyr/boards/nxp/frdm_k22f/frdm_k22f.dts:92 */
		user_button_3: button_1 {
			label = "User SW3";          /* in zephyr/boards/nxp/frdm_k22f/frdm_k22f.dts:93 */
			gpios = < &gpiob 0x11 0x1 >; /* in zephyr/boards/nxp/frdm_k22f/frdm_k22f.dts:94 */
			zephyr,code = < 0x2 >;       /* in zephyr/boards/nxp/frdm_k22f/frdm_k22f.dts:95 */
		};
	};

	/* node '/connector' defined in zephyr/boards/nxp/frdm_k22f/frdm_k22f.dts:99 */
	arduino_header: connector {
		compatible = "arduino-header-r3";          /* in zephyr/boards/nxp/frdm_k22f/frdm_k22f.dts:100 */
		#gpio-cells = < 0x2 >;                     /* in zephyr/boards/nxp/frdm_k22f/frdm_k22f.dts:101 */
		gpio-map-mask = < 0xffffffff 0xffffffc0 >; /* in zephyr/boards/nxp/frdm_k22f/frdm_k22f.dts:102 */
		gpio-map-pass-thru = < 0x0 0x3f >;         /* in zephyr/boards/nxp/frdm_k22f/frdm_k22f.dts:103 */
		gpio-map = < 0x0 0x0 &gpiob 0x0 0x0 >,
		           < 0x1 0x0 &gpiob 0x1 0x0 >,
		           < 0x2 0x0 &gpioc 0x1 0x0 >,
		           < 0x3 0x0 &gpioc 0x2 0x0 >,
		           < 0x4 0x0 &gpiob 0x3 0x0 >,
		           < 0x5 0x0 &gpiob 0x2 0x0 >,
		           < 0x6 0x0 &gpiod 0x2 0x0 >,
		           < 0x7 0x0 &gpiod 0x3 0x0 >,
		           < 0x8 0x0 &gpiob 0x10 0x0 >,
		           < 0x9 0x0 &gpioa 0x2 0x0 >,
		           < 0xa 0x0 &gpioa 0x4 0x0 >,
		           < 0xb 0x0 &gpiob 0x12 0x0 >,
		           < 0xc 0x0 &gpioc 0x3 0x0 >,
		           < 0xd 0x0 &gpioc 0x6 0x0 >,
		           < 0xe 0x0 &gpiob 0x13 0x0 >,
		           < 0xf 0x0 &gpioa 0x1 0x0 >,
		           < 0x10 0x0 &gpiod 0x4 0x0 >,
		           < 0x11 0x0 &gpiod 0x6 0x0 >,
		           < 0x12 0x0 &gpiod 0x7 0x0 >,
		           < 0x13 0x0 &gpiod 0x5 0x0 >,
		           < 0x14 0x0 &gpioe 0x0 0x0 >,
		           < 0x15 0x0 &gpioe 0x1 0x0 >;    /* in zephyr/boards/nxp/frdm_k22f/frdm_k22f.dts:104 */
	};
};
